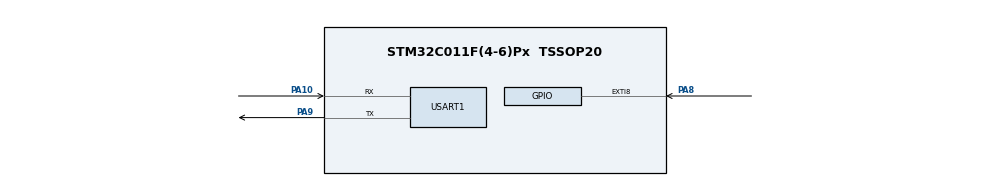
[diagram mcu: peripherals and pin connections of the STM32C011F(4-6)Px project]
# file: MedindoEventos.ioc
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Mcu.Family=STM32C0
Mcu.Name=STM32C011F(4-6)Px
Mcu.Package=TSSOP20
NVIC.EXTI4_15_IRQn=true\:0\:0\:false\:false\:true\:true\:true\:true
NVIC.TIM3_IRQn=true\:0\:0\:false\:false\:true\:true\:true\:true
PA10\ [PA12].Mode=Asynchronous
PA10\ [PA12].Signal=USART1_RX
PA13.Mode=Serial_Wire
PA13.Signal=DEBUG_SWDIO
PA14-BOOT0.Mode=Serial_Wire
PA14-BOOT0.Signal=DEBUG_SWCLK
PA8.GPIO_ModeDefaultEXTI=GPIO_MODE_IT_FALLING
PA8.GPIO_PuPd=GPIO_PULLUP
PA8.Signal=GPXTI8
PA9\ [PA11].Mode=Asynchronous
PA9\ [PA11].Signal=USART1_TX
ProjectManager.HeapSize=0x200
ProjectManager.StackSize=0x400
ProjectManager.TargetToolchain=STM32CubeIDE
RCC.ADCFreq_Value=48000000
RCC.AHBFreq_Value=48000000
RCC.CortexFreq_Value=48000000
RCC.EXTERNAL_CLOCK_VALUE=12288000
RCC.HCLKFreq_Value=48000000
RCC.HSE_VALUE=8000000
RCC.HSISYSCLKDivider=RCC_HSI_DIV1
RCC.HSI_VALUE=48000000
RCC.LSE_VALUE=32768
RCC.SYSCLKFreq_VALUE=48000000
TIM3.AutoReloadPreload=TIM_AUTORELOAD_PRELOAD_ENABLE
TIM3.Period=10-1
TIM3.Prescaler=4800-1
USART1.VirtualMode-Asynchronous=VM_ASYNC
VP_SYS_VS_PINREMAP.Mode=PINREMAP
VP_SYS_VS_PINREMAP_10_12.Mode=PINREMAP_10_12
VP_TIM3_VS_ClockSourceINT.Mode=Internal
board=custom

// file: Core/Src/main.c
/* USER CODE BEGIN Header */
/**
  ******************************************************************************
  * @file           : main.c
  * @brief          : Main program body
  ******************************************************************************
  * @attention
  *
  * Copyright (c) 2024 STMicroelectronics.
  * All rights reserved.
  *
  * This software is licensed under terms that can be found in the LICENSE file
  * in the root directory of this software component.
  * If no LICENSE file comes with this software, it is provided AS-IS.
  *
  ******************************************************************************
  */
/* USER CODE END Header */
#include "main.h"
#include "stdio.h"
#include "string.h"

TIM_HandleTypeDef htim3;

UART_HandleTypeDef huart1;

/* USER CODE BEGIN PV */
/* Variáveis globais */
volatile  uint32_t time = 0;
volatile  uint8_t button_state = 0;
char uart_tx_buffer[50];
uint8_t msg_start[] = "Contagem de tempo iniciada!\r\n";
/* USER CODE END PV */

void SystemClock_Config(void);
static void MX_GPIO_Init(void);
static void MX_USART1_UART_Init(void);
static void MX_TIM3_Init(void);

int main(void)
{

  /* MCU Configuration--------------------------------------------------------*/

  /* Reset of all peripherals, Initializes the Flash interface and the Systick. */
  HAL_Init();

  /* Configure the system clock */
  SystemClock_Config();

  /* Initialize all configured peripherals */
  MX_GPIO_Init();
  MX_USART1_UART_Init();
  MX_TIM3_Init();

  /* Infinite loop */
  while (1)
  {

  }
}

/* Função de callback de interrupção do temporizador */
void HAL_TIM_PeriodElapsedCallback(TIM_HandleTypeDef *htim) {
    if (htim == &htim3) {
        time++;
    }
}

/* Função de configuração da interrupção externa */
void HAL_GPIO_EXTI_Falling_Callback(uint16_t GPIO_Pin) {
    if (GPIO_Pin == GPIO_PIN_8) { // Botão pressionado
    	if (!button_state) { // Primeiro pressionamento
    		HAL_TIM_Base_Start_IT(&htim3);     // Inicia temporizador
    	    HAL_UART_Transmit(&huart1, msg_start, (sizeof(msg_start)-1), 1000);	// Transmite mensagem serial pela UART
    	    button_state = 1;
    	} else { // Segundo pressionamento
    		HAL_TIM_Base_Stop_IT(&htim3); // Para temporizador
    	    sprintf(uart_tx_buffer, "Tempo decorrido: %lu ms\r\n", time); // Formata mensagem
    	    HAL_UART_Transmit(&huart1, (uint8_t *)uart_tx_buffer, strlen(uart_tx_buffer), 1000); // Transmite mensagem serial pela UART
    	    //zera variaveis de controle
    	    time = 0;
    	    button_state = 0;
    	 }
    }
}

void SystemClock_Config(void)
{
  RCC_OscInitTypeDef RCC_OscInitStruct = {0};
  RCC_ClkInitTypeDef RCC_ClkInitStruct = {0};

  /** Initializes the RCC Oscillators according to the specified parameters
  * in the RCC_OscInitTypeDef structure.
  */
  RCC_OscInitStruct.OscillatorType = RCC_OSCILLATORTYPE_HSI;
  RCC_OscInitStruct.HSIState = RCC_HSI_ON;
  RCC_OscInitStruct.HSIDiv = RCC_HSI_DIV1;
  RCC_OscInitStruct.HSICalibrationValue = RCC_HSICALIBRATION_DEFAULT;
  if (HAL_RCC_OscConfig(&RCC_OscInitStruct) != HAL_OK)
  {
    Error_Handler();
  }

  /** Initializes the CPU, AHB and APB buses clocks
  */
  RCC_ClkInitStruct.ClockType = RCC_CLOCKTYPE_HCLK|RCC_CLOCKTYPE_SYSCLK
                              |RCC_CLOCKTYPE_PCLK1;
  RCC_ClkInitStruct.SYSCLKSource = RCC_SYSCLKSOURCE_HSI;
  RCC_ClkInitStruct.SYSCLKDivider = RCC_SYSCLK_DIV1;
  RCC_ClkInitStruct.AHBCLKDivider = RCC_HCLK_DIV1;
  RCC_ClkInitStruct.APB1CLKDivider = RCC_APB1_DIV1;

  if (HAL_RCC_ClockConfig(&RCC_ClkInitStruct, FLASH_LATENCY_1) != HAL_OK)
  {
    Error_Handler();
  }
}

static void MX_TIM3_Init(void)
{

  TIM_ClockConfigTypeDef sClockSourceConfig = {0};
  TIM_MasterConfigTypeDef sMasterConfig = {0};

  htim3.Instance = TIM3;
  htim3.Init.Prescaler = 4800-1;
  htim3.Init.CounterMode = TIM_COUNTERMODE_UP;
  htim3.Init.Period = 10-1;
  htim3.Init.ClockDivision = TIM_CLOCKDIVISION_DIV1;
  htim3.Init.AutoReloadPreload = TIM_AUTORELOAD_PRELOAD_ENABLE;
  if (HAL_TIM_Base_Init(&htim3) != HAL_OK)
  {
    Error_Handler();
  }
  sClockSourceConfig.ClockSource = TIM_CLOCKSOURCE_INTERNAL;
  if (HAL_TIM_ConfigClockSource(&htim3, &sClockSourceConfig) != HAL_OK)
  {
    Error_Handler();
  }
  sMasterConfig.MasterOutputTrigger = TIM_TRGO_RESET;
  sMasterConfig.MasterSlaveMode = TIM_MASTERSLAVEMODE_DISABLE;
  if (HAL_TIMEx_MasterConfigSynchronization(&htim3, &sMasterConfig) != HAL_OK)
  {
    Error_Handler();
  }

}

static void MX_USART1_UART_Init(void)
{

  huart1.Instance = USART1;
  huart1.Init.BaudRate = 115200;
  huart1.Init.WordLength = UART_WORDLENGTH_8B;
  huart1.Init.StopBits = UART_STOPBITS_1;
  huart1.Init.Parity = UART_PARITY_NONE;
  huart1.Init.Mode = UART_MODE_TX_RX;
  huart1.Init.HwFlowCtl = UART_HWCONTROL_NONE;
  huart1.Init.OverSampling = UART_OVERSAMPLING_16;
  huart1.Init.OneBitSampling = UART_ONE_BIT_SAMPLE_DISABLE;
  huart1.Init.ClockPrescaler = UART_PRESCALER_DIV1;
  huart1.AdvancedInit.AdvFeatureInit = UART_ADVFEATURE_NO_INIT;
  if (HAL_UART_Init(&huart1) != HAL_OK)
  {
    Error_Handler();
  }
  if (HAL_UARTEx_SetTxFifoThreshold(&huart1, UART_TXFIFO_THRESHOLD_1_8) != HAL_OK)
  {
    Error_Handler();
  }
  if (HAL_UARTEx_SetRxFifoThreshold(&huart1, UART_RXFIFO_THRESHOLD_1_8) != HAL_OK)
  {
    Error_Handler();
  }
  if (HAL_UARTEx_DisableFifoMode(&huart1) != HAL_OK)
  {
    Error_Handler();
  }

}

static void MX_GPIO_Init(void)
{
  GPIO_InitTypeDef GPIO_InitStruct = {0};

  /* GPIO Ports Clock Enable */
  __HAL_RCC_GPIOA_CLK_ENABLE();

  /*Configure GPIO pin : PA8 */
  GPIO_InitStruct.Pin = GPIO_PIN_8;
  GPIO_InitStruct.Mode = GPIO_MODE_IT_FALLING;
  GPIO_InitStruct.Pull = GPIO_PULLUP;
  HAL_GPIO_Init(GPIOA, &GPIO_InitStruct);

  /* EXTI interrupt init*/
  HAL_NVIC_SetPriority(EXTI4_15_IRQn, 0, 0);
  HAL_NVIC_EnableIRQ(EXTI4_15_IRQn);

}

void Error_Handler(void)
{
  __disable_irq();
  while (1)
  {
  }
}
